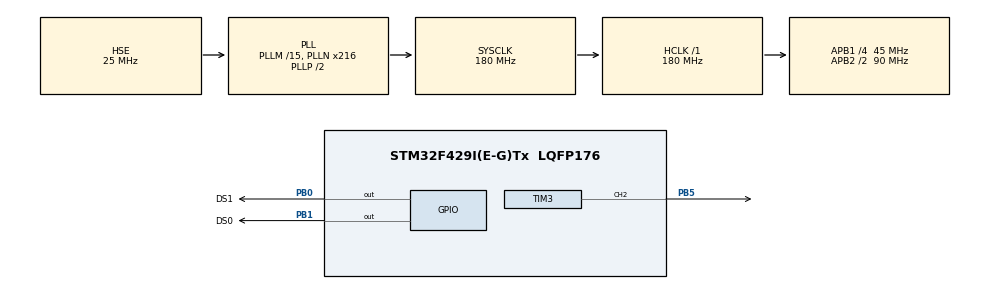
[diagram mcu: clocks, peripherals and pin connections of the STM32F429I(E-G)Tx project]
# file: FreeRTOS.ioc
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FREERTOS.Tasks01=MyFirstTask,24,128,StartMyFirstTask,Default,NULL,Dynamic,NULL,NULL;myTask02,8,128,StartTask02,Default,NULL,Dynamic,NULL,NULL;myTask03,8,128,StartTask03,Default,NULL,Dynamic,NULL,NULL
Mcu.Family=STM32F4
Mcu.Name=STM32F429I(E-G)Tx
Mcu.Package=LQFP176
NVIC.PriorityGroup=NVIC_PRIORITYGROUP_4
NVIC.TIM1_UP_TIM10_IRQn=true\:15\:0\:false\:false\:true\:false\:false\:true\:true
NVIC.TimeBase=TIM1_UP_TIM10_IRQn
NVIC.TimeBaseIP=TIM1
PB0.GPIO_Label=DS1
PB0.Signal=GPIO_Output
PB1.GPIO_Label=DS0
PB1.Signal=GPIO_Output
PB5.Signal=S_TIM3_CH2
PH0/OSC_IN.Mode=HSE-External-Oscillator
PH0/OSC_IN.Signal=RCC_OSC_IN
PH1/OSC_OUT.Mode=HSE-External-Oscillator
PH1/OSC_OUT.Signal=RCC_OSC_OUT
ProjectManager.HeapSize=0x200
ProjectManager.StackSize=0x400
ProjectManager.TargetToolchain=MDK-ARM V5.32
RCC.48MHZClocksFreq_Value=90000000
RCC.AHBFreq_Value=180000000
RCC.APB1CLKDivider=RCC_HCLK_DIV4
RCC.APB1Freq_Value=45000000
RCC.APB1TimFreq_Value=90000000
RCC.APB2CLKDivider=RCC_HCLK_DIV2
RCC.APB2Freq_Value=90000000
RCC.APB2TimFreq_Value=180000000
RCC.CortexFreq_Value=180000000
RCC.HCLKFreq_Value=180000000
RCC.HSE_VALUE=25000000
RCC.HSI_VALUE=16000000
RCC.LSE_VALUE=32768
RCC.PLLM=15
RCC.PLLN=216
RCC.PLLSourceVirtual=RCC_PLLSOURCE_HSE
RCC.SYSCLKFreq_VALUE=180000000
RCC.SYSCLKSource=RCC_SYSCLKSOURCE_PLLCLK
RCC.VCOOutputFreq_Value=360000000
SH.S_TIM3_CH2.0=TIM3_CH2,PWM Generation2 CH2
TIM3.Channel-PWM\ Generation2\ CH2=TIM_CHANNEL_2
TIM3.Period=999
TIM3.Prescaler=89
TIM3.Pulse-PWM\ Generation2\ CH2=500
VP_FREERTOS_VS_CMSIS_V2.Mode=CMSIS_V2
VP_SYS_VS_tim1.Mode=TIM1
VP_TIM3_VS_ClockSourceINT.Mode=Internal
board=custom

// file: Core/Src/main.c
/* USER CODE BEGIN Header */
/**
  ******************************************************************************
  * @file           : main.c
  * @brief          : Main program body
  ******************************************************************************
  * @attention
  *
  * Copyright (c) 2025 STMicroelectronics.
  * All rights reserved.
  *
  * This software is licensed under terms that can be found in the LICENSE file
  * in the root directory of this software component.
  * If no LICENSE file comes with this software, it is provided AS-IS.
  *
  ******************************************************************************
  */
/* USER CODE END Header */
#include "main.h"
#include "cmsis_os.h"
#include "tim.h"
#include "gpio.h"

void SystemClock_Config(void);
void MX_FREERTOS_Init(void);

int main(void)
{

  /* MCU Configuration--------------------------------------------------------*/

  /* Reset of all peripherals, Initializes the Flash interface and the Systick. */
  HAL_Init();

  /* Configure the system clock */
  SystemClock_Config();

  /* Initialize all configured peripherals */
  MX_GPIO_Init();
  MX_TIM3_Init();

  /* Init scheduler */
  osKernelInitialize();  /* Call init function for freertos objects (in cmsis_os2.c) */
  MX_FREERTOS_Init();

  /* Start scheduler */
  osKernelStart();

  /* We should never get here as control is now taken by the scheduler */

  /* Infinite loop */
  while (1)
  {

  }
}

void SystemClock_Config(void)
{
  RCC_OscInitTypeDef RCC_OscInitStruct = {0};
  RCC_ClkInitTypeDef RCC_ClkInitStruct = {0};

  /** Configure the main internal regulator output voltage
  */
  __HAL_RCC_PWR_CLK_ENABLE();
  __HAL_PWR_VOLTAGESCALING_CONFIG(PWR_REGULATOR_VOLTAGE_SCALE1);

  /** Initializes the RCC Oscillators according to the specified parameters
  * in the RCC_OscInitTypeDef structure.
  */
  RCC_OscInitStruct.OscillatorType = RCC_OSCILLATORTYPE_HSE;
  RCC_OscInitStruct.HSEState = RCC_HSE_ON;
  RCC_OscInitStruct.PLL.PLLState = RCC_PLL_ON;
  RCC_OscInitStruct.PLL.PLLSource = RCC_PLLSOURCE_HSE;
  RCC_OscInitStruct.PLL.PLLM = 15;
  RCC_OscInitStruct.PLL.PLLN = 216;
  RCC_OscInitStruct.PLL.PLLP = RCC_PLLP_DIV2;
  RCC_OscInitStruct.PLL.PLLQ = 4;
  if (HAL_RCC_OscConfig(&RCC_OscInitStruct) != HAL_OK)
  {
    Error_Handler();
  }

  /** Activate the Over-Drive mode
  */
  if (HAL_PWREx_EnableOverDrive() != HAL_OK)
  {
    Error_Handler();
  }

  /** Initializes the CPU, AHB and APB buses clocks
  */
  RCC_ClkInitStruct.ClockType = RCC_CLOCKTYPE_HCLK|RCC_CLOCKTYPE_SYSCLK
                              |RCC_CLOCKTYPE_PCLK1|RCC_CLOCKTYPE_PCLK2;
  RCC_ClkInitStruct.SYSCLKSource = RCC_SYSCLKSOURCE_PLLCLK;
  RCC_ClkInitStruct.AHBCLKDivider = RCC_SYSCLK_DIV1;
  RCC_ClkInitStruct.APB1CLKDivider = RCC_HCLK_DIV4;
  RCC_ClkInitStruct.APB2CLKDivider = RCC_HCLK_DIV2;

  if (HAL_RCC_ClockConfig(&RCC_ClkInitStruct, FLASH_LATENCY_5) != HAL_OK)
  {
    Error_Handler();
  }
}

void HAL_TIM_PeriodElapsedCallback(TIM_HandleTypeDef *htim)
{
  if (htim->Instance == TIM1)
  {
    HAL_IncTick();
  }
}

void Error_Handler(void)
{
  __disable_irq();
  while (1)
  {
  }
}

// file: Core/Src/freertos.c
/* USER CODE BEGIN Header */
/**
  ******************************************************************************
  * File Name          : freertos.c
  * Description        : Code for freertos applications
  ******************************************************************************
  * @attention
  *
  * Copyright (c) 2025 STMicroelectronics.
  * All rights reserved.
  *
  * This software is licensed under terms that can be found in the LICENSE file
  * in the root directory of this software component.
  * If no LICENSE file comes with this software, it is provided AS-IS.
  *
  ******************************************************************************
  */
/* USER CODE END Header */

#include "FreeRTOS.h"
#include "task.h"
#include "main.h"
#include "cmsis_os.h"

/* USER CODE BEGIN Includes */
//extern TIM_HandleTypeDef htim3;
/* USER CODE END Includes */

/* USER CODE BEGIN PD */
#define BLINK_TIME 100
/* USER CODE END PD */

/* Definitions for MyFirstTask */
osThreadId_t MyFirstTaskHandle;
const osThreadAttr_t MyFirstTask_attributes = {
  .name = "MyFirstTask",
  .stack_size = 128 * 4,
  .priority = (osPriority_t) osPriorityNormal,
};
/* Definitions for myTask02 */
osThreadId_t myTask02Handle;
const osThreadAttr_t myTask02_attributes = {
  .name = "myTask02",
  .stack_size = 128 * 4,
  .priority = (osPriority_t) osPriorityLow,
};
/* Definitions for myTask03 */
osThreadId_t myTask03Handle;
const osThreadAttr_t myTask03_attributes = {
  .name = "myTask03",
  .stack_size = 128 * 4,
  .priority = (osPriority_t) osPriorityLow,
};

void StartMyFirstTask(void *argument);
void StartTask02(void *argument);
void StartTask03(void *argument);

void MX_FREERTOS_Init(void); /* (MISRA C 2004 rule 8.1) */

void MX_FREERTOS_Init(void) {

  /* Create the thread(s) */
  /* creation of MyFirstTask */
  MyFirstTaskHandle = osThreadNew(StartMyFirstTask, NULL, &MyFirstTask_attributes);

  /* creation of myTask02 */
  myTask02Handle = osThreadNew(StartTask02, NULL, &myTask02_attributes);

  /* creation of myTask03 */
  myTask03Handle = osThreadNew(StartTask03, NULL, &myTask03_attributes);

}

void StartMyFirstTask(void *argument)
{
  /* USER CODE BEGIN StartMyFirstTask */
  /* Infinite loop */
  for(;;)
  {
		HAL_GPIO_TogglePin(DS0_GPIO_Port,DS0_Pin);
		osDelay(BLINK_TIME);
  }
  /* USER CODE END StartMyFirstTask */
}

void StartTask02(void *argument)
{
  /* USER CODE BEGIN StartTask02 */
  /* Infinite loop */
	osDelay(BLINK_TIME);
  for(;;)
  {
    HAL_GPIO_TogglePin(DS1_GPIO_Port,DS1_Pin);
		osDelay(BLINK_TIME);
  }
  /* USER CODE END StartTask02 */
}

void StartTask03(void *argument)
{
  /* USER CODE BEGIN StartTask03 */
		HAL_TIM_PWM_Start(&htim3, TIM_CHANNEL_2);
  /* Infinite loop */
  for(;;)
  {
		//__HAL_TIM_SET_COMPARE(&htim3, TIM_CHANNEL_2,400);

		for(int i=0;i<1000;i+=10){
      __HAL_TIM_SET_COMPARE(&htim3, TIM_CHANNEL_2, i);
		  osDelay(5);
    }
		//osDelay(200);

    for(int i=1000;i>0;i-=10){
      __HAL_TIM_SET_COMPARE(&htim3, TIM_CHANNEL_2, i);
		  osDelay(5);
    }

  }
  /* USER CODE END StartTask03 */
}
